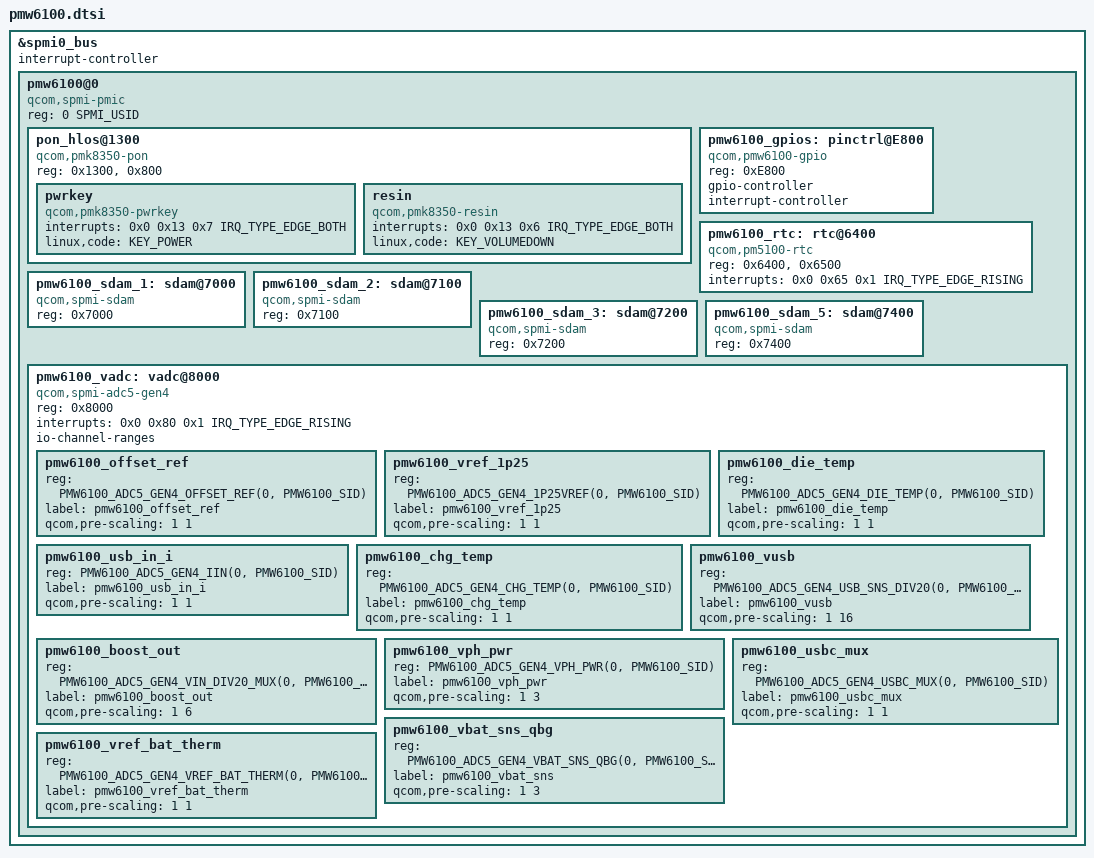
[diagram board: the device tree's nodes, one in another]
// SPDX-License-Identifier: BSD-3-Clause
/*
 *Copyright (c) 2025 Qualcomm Innovation Center, Inc. All rights reserved.
 */
#include <dt-bindings/input/input.h>
#include <dt-bindings/interrupt-controller/irq.h>
#include <dt-bindings/spmi/spmi.h>
#include <dt-bindings/iio/qcom,spmi-adc5-gen4-pmw6100.h>

&spmi0_bus {
	#address-cells = <2>;
	#size-cells = <0>;
	interrupt-controller;
	#interrupt-cells = <4>;

	pmw6100@0 {
		compatible = "qcom,spmi-pmic";
		reg = <0 SPMI_USID>;
		#address-cells = <1>;
		#size-cells = <0>;

		pon_hlos@1300 {
			compatible = "qcom,pmk8350-pon";
			reg = <0x1300>, <0x800>;
			reg-names = "hlos", "pbs";

			pwrkey {
				compatible = "qcom,pmk8350-pwrkey";
				interrupts = <0x0 0x13 0x7 IRQ_TYPE_EDGE_BOTH>;
				linux,code = <KEY_POWER>;
			};

			resin {
				compatible = "qcom,pmk8350-resin";
				interrupts = <0x0 0x13 0x6 IRQ_TYPE_EDGE_BOTH>;
				linux,code = <KEY_VOLUMEDOWN>;
			};
		};

		pmw6100_gpios: pinctrl@E800 {
			compatible = "qcom,pmw6100-gpio";
			reg = <0xE800>;
			gpio-controller;
			#gpio-cells = <2>;
			interrupt-controller;
			#interrupt-cells = <2>;
		};

		pmw6100_rtc: rtc@6400 {
			compatible = "qcom,pm5100-rtc";
			reg = <0x6400>, <0x6500>;
			reg-names = "rtc", "alarm";
			interrupts = <0x0 0x65 0x1 IRQ_TYPE_EDGE_RISING>;
		};

		pmw6100_sdam_1: sdam@7000 {
			compatible = "qcom,spmi-sdam";
			reg = <0x7000>;
			#address-cells = <1>;
			#size-cells = <1>;
		};

		pmw6100_sdam_2: sdam@7100 {
			compatible = "qcom,spmi-sdam";
			reg = <0x7100>;
			#address-cells = <1>;
			#size-cells = <1>;
		};

		pmw6100_sdam_3: sdam@7200 {
			compatible = "qcom,spmi-sdam";
			reg = <0x7200>;
		};

		pmw6100_sdam_5: sdam@7400 {
			compatible = "qcom,spmi-sdam";
			reg = <0x7400>;
		};

		pmw6100_vadc: vadc@8000 {
			compatible = "qcom,spmi-adc5-gen4";
			reg = <0x8000>;
			#address-cells = <1>;
			#size-cells = <0>;
			interrupts = <0x0 0x80 0x1 IRQ_TYPE_EDGE_RISING>;
			interrupt-names = "adc-sdam0";
			#thermal-sensor-cells = <1>;
			#io-channel-cells = <1>;
			io-channel-ranges;
			/* Lando ADC Channels */
			pmw6100_offset_ref {
				reg = <PMW6100_ADC5_GEN4_OFFSET_REF(0, PMW6100_SID)>;
				label = "pmw6100_offset_ref";
				qcom,pre-scaling = <1 1>;
			};

			pmw6100_vref_1p25 {
				reg = <PMW6100_ADC5_GEN4_1P25VREF(0, PMW6100_SID)>;
				label = "pmw6100_vref_1p25";
				qcom,pre-scaling = <1 1>;
			};

			pmw6100_die_temp {
				reg = <PMW6100_ADC5_GEN4_DIE_TEMP(0, PMW6100_SID)>;
				label = "pmw6100_die_temp";
				qcom,pre-scaling = <1 1>;
			};

			pmw6100_usb_in_i {
				reg = <PMW6100_ADC5_GEN4_IIN(0, PMW6100_SID)>;
				label = "pmw6100_usb_in_i";
				qcom,pre-scaling = <1 1>;
			};

			pmw6100_chg_temp {
				reg = <PMW6100_ADC5_GEN4_CHG_TEMP(0, PMW6100_SID)>;
				label = "pmw6100_chg_temp";
				qcom,pre-scaling = <1 1>;
			};

			pmw6100_vusb {
				reg = <PMW6100_ADC5_GEN4_USB_SNS_DIV20(0, PMW6100_SID)>;
				label = "pmw6100_vusb";
				qcom,pre-scaling = <1 16>;
			};

			pmw6100_boost_out {
				reg = <PMW6100_ADC5_GEN4_VIN_DIV20_MUX(0, PMW6100_SID)>;
				label = "pmw6100_boost_out";
				qcom,pre-scaling = <1 6>;
			};

			pmw6100_vph_pwr {
				reg = <PMW6100_ADC5_GEN4_VPH_PWR(0, PMW6100_SID)>;
				label = "pmw6100_vph_pwr";
				qcom,pre-scaling = <1 3>;
			};

			pmw6100_vbat_sns_qbg {
				reg = <PMW6100_ADC5_GEN4_VBAT_SNS_QBG(0, PMW6100_SID)>;
				label = "pmw6100_vbat_sns";
				qcom,pre-scaling = <1 3>;
			};

			pmw6100_usbc_mux {
				reg = <PMW6100_ADC5_GEN4_USBC_MUX(0, PMW6100_SID)>;
				label = "pmw6100_usbc_mux";
				qcom,pre-scaling = <1 1>;
			};

			pmw6100_vref_bat_therm {
				reg = <PMW6100_ADC5_GEN4_VREF_BAT_THERM(0, PMW6100_SID)>;
				label = "pmw6100_vref_bat_therm";
				qcom,pre-scaling = <1 1>;
			};
		};
	};
};
